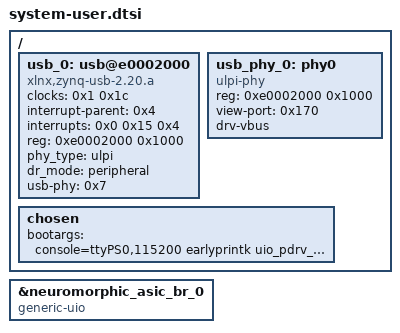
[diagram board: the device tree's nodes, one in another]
/include/ "system-conf.dtsi"
/ {
    usb_0: usb@e0002000 {
     compatible = "xlnx,zynq-usb-2.20.a", "chipidea,usb2";
     clocks = <0x1 0x1c>;
     interrupt-parent = <0x4>;
     interrupts = <0x0 0x15 0x4>;
     reg = <0xe0002000 0x1000>;
     phy_type = "ulpi";
    dr_mode = "peripheral";
    usb-phy = <0x7>;
        
     };
usb_phy_0: phy0 {
    compatible = "ulpi-phy";
    #phy-cells = <0>;
    reg = <0xe0002000 0x1000>;
    view-port = <0x170>;
    drv-vbus;
    linux,phandle = <0x7>;
    phandle = <0x7>;
   };

chosen {
        bootargs = "console=ttyPS0,115200 earlyprintk uio_pdrv_genirq.of_id=generic-uio root=/dev/mmcblk0p2 init=/sbin/init";
    };
};
&neuromorphic_asic_br_0 {
    compatible = "generic-uio";
};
